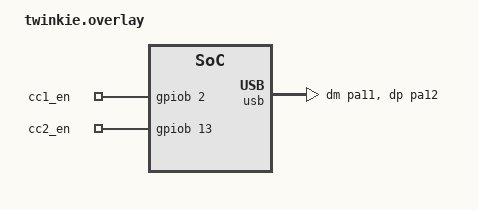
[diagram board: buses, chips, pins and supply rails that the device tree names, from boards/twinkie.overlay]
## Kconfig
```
# Private config options for eSPI sample app

# Copyright (c) 2019 Intel Corporation
# SPDX-License-Identifier: Apache-2.0

config STM32_UCPD
        bool "USBC TCPC device controller driver"
        depends on SOC_FAMILY_STM32
        default y
	select USE_STM32_LL_BUS
	select USE_STM32_LL_SYSTEM
	select USE_STM32_LL_RCC
	select USE_STM32_LL_DMA
        select USE_STM32_LL_UCPD
	select USE_STM32_LL_USB
	select USE_STM32_HAL_PCD
	select USE_STM32_HAL_PCD_EX
        help
          Enable USBC TCPC support on the STM32 G0, G4, L5, and U5 family of
          processors.

source "Kconfig.zephyr"
```

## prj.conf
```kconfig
CONFIG_ZTEST=y
CONFIG_ZTEST_NEW_API=y

CONFIG_SMF=y

CONFIG_USB_CDC_ACM_LOG_LEVEL_OFF=y

CONFIG_USB_DEVICE_STACK=y
CONFIG_USB_COMPOSITE_DEVICE=y
CONFIG_USB_CDC_ACM_RINGBUF_SIZE=512

CONFIG_SERIAL=y
CONFIG_CONSOLE=y
CONFIG_UART_CONSOLE=y
CONFIG_UART_INTERRUPT_DRIVEN=y

CONFIG_PRINTK=y
CONFIG_SHELL=y
CONFIG_SHELL_STACK_SIZE=1024
CONFIG_SHELL_BACKEND_SERIAL=y

CONFIG_THREAD_MONITOR=y
CONFIG_INIT_STACKS=y
CONFIG_BOOT_BANNER=n
CONFIG_THREAD_NAME=y
CONFIG_CBPRINTF_NANO=y

CONFIG_ADC=y
CONFIG_ADC_STM32=y
CONFIG_ADC_SHELL=y
CONFIG_GPIO=y

CONFIG_ADC_STM32_SHARED_IRQS=n

CONFIG_USB_DC_STM32=n
```

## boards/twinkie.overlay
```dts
/ {
	chosen {
		zephyr,shell_uart = &cdc_acm_uart0;
		zephyr,console = &cdc_acm_uart1;
	};

	cc_config {
		compatible = "gpio-leds";
		cc1_en: cc1en {
			gpios = <&gpiob 2 GPIO_ACTIVE_HIGH>;
		};

		cc2_en: cc2en {
			gpios = <&gpiob 13 GPIO_ACTIVE_HIGH>;
		};
	};
	
	aliases {
		encc1 = &cc1_en;
		encc2 = &cc2_en;
	};
};

zephyr_udc0: &usb {
	/* Twinkie V2 Command Shell */
	cdc_acm_uart0: cdc_acm_uart0 {
		compatible = "zephyr,cdc-acm-uart";
	};

	/* Twinkie V2 Packet Logging */
	cdc_acm_uart1: cdc_acm_uart1 {
		compatible = "zephyr,cdc-acm-uart";
	};

	pinctrl-0 = <&usb_dm_pa11 &usb_dp_pa12>;
	pinctrl-names = "default";
	status = "okay";
};
```

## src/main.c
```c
/*
 * Copyright (c) 2021 Legrand North America, LLC.
 *
 * SPDX-License-Identifier: Apache-2.0
 */

/*
 * @file test custom_lib library
 *
 * This suite verifies that the methods provided with the custom_lib
 * library works correctly.
 */

#include <limits.h>

#include <zephyr/ztest.h>

ZTEST(custom_lib, test_get_value)
{

}

ZTEST_SUITE(custom_lib, NULL, NULL, NULL, NULL, NULL);
```
